# TOP_CTRL_TOP_CTRL_50D80000h register map
Vendor: Texas Instruments
Peripheral module from a debugger description file (folder AM263P).
Registers are 32-bit, read-write, reset 0x0 unless marked. A register's access mark holds for its fields unless they carry their own. Offsets are as the file gives them; lines under a group give offsets from that group; [hi:lo] are bit positions; {n}, {i} and the like mark numbered series; 'fields as' and 'values as' point back to an identical list; <NAME> marks a mode.

## TOP_CTRL
{0x10+4i} TOP_CTRL_EFUSE_DIEID{i} ro (i=0..3) — EFUSE_DIEID{i}.
  [31:0] EFUSE_DIEID{i}_VAL — EFUSE DieID[{32i+31}:{32i}]
{0x20+4i} TOP_CTRL_EFUSE_UID{i} ro (i=0..2) — EFUSE_UID{i}.
  [31:0] EFUSE_UID{i}_VAL — EFUSE UID[{32i+31}:{32i}]- Unique ID
0x2C TOP_CTRL_EFUSE_UID3 ro — EFUSE_UID3.
  [23:0] EFUSE_UID3_VAL — EFUSE UID[120:96]- Unique ID
0x30 TOP_CTRL_EFUSE_DEVICE_TYPE ro — EFUSE_DEVICE_TYPE.
  [15:0] EFUSE_DEVICE_TYPE_VAL — EFUSE Device Type : 0x5 - Test Device 0x3 - General Purpose Device 0x9 - EMU Device 0xA - High Secure
0x34 TOP_CTRL_EFUSE_FROM0_CHECKSUM ro — EFUSE_FROM0_CHECKSUM.
  [31:0] EFUSE_FROM0_CHECKSUM_VAL — 32 bit FROM0 Checksum
0x38 TOP_CTRL_EFUSE_JTAG_USERCODE_ID ro — EFUSE_JTAG_USERCODE_ID.
  [31:0] EFUSE_JTAG_USERCODE_ID_VAL — EFUSE JTAG_USER_CODE_ID[31:0]. Denotes part variant
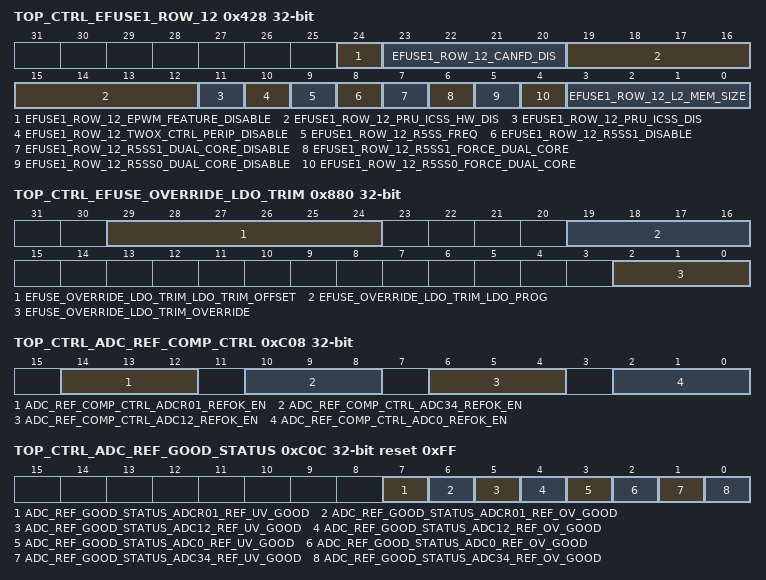
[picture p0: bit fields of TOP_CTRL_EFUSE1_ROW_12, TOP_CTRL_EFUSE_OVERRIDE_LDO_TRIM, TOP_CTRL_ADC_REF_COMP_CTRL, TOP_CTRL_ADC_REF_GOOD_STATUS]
0x428 TOP_CTRL_EFUSE1_ROW_12 ro — EFUSE Row.
  [24] EFUSE1_ROW_12_EPWM_FEATURE_DISABLE — Customer protected features inside PWM IP 1'b0 - All features enabled1'b1 - Customer defined features are protected
  [23:20] EFUSE1_ROW_12_CANFD_DIS — CANFD disables. Bit positions correspond to CAN instance. 1'b0 - CAN is enabled1'b1 - CAN is disabled
  [19:12] EFUSE1_ROW_12_PRU_ICSS_HW_DIS — ICSSM IP feature configuration0x00:EtherCAT is available0x03:EtherCAT is disabled
  [11] EFUSE1_ROW_12_PRU_ICSS_DIS — ICSSM IP disable1'b0 - ICSSM enabled1'b1 - ICSSM disabled
  [10] EFUSE1_ROW_12_TWOX_CTRL_PERIP_DISABLE — 2x control IPs enabled1'b0 - 1x control IPs available (Standard Analog Configuration)1'b1 - (i.e.all) 2x control IPs available (Enhanced Analog Configuration) Refer to device datasheet for more details on the control IP Counts
  [9] EFUSE1_ROW_12_R5SS_FREQ — R5SS Freq1'b0 - 400 MHz1'b1 - 200 MHz
  [8] EFUSE1_ROW_12_R5SS1_DISABLE — R5SS1 Disabled
  [7] EFUSE1_ROW_12_R5SS1_DUAL_CORE_DISABLE — Force Lock step
  [6] EFUSE1_ROW_12_R5SS1_FORCE_DUAL_CORE — Force Dual core
  [5] EFUSE1_ROW_12_R5SS0_DUAL_CORE_DISABLE — Force Lock step
  [4] EFUSE1_ROW_12_R5SS0_FORCE_DUAL_CORE — Force Dual core
  [3:0] EFUSE1_ROW_12_L2_MEM_SIZE — Decides memory size0000L2-3.0 MB0001L2-2.5 MB0010L2-2.0 MB0011L2-1.5 MB0100L2-1.0 MB0101L2-0.5 MBOthers-Reserved
0x500 TOP_CTRL_MAC_ID0 ro — Ethernet MAC address lower 32-bits.
  [31:0] MAC_ID0_MACID_LO — 48-bit Ethernet MAC_ID field [can be used by SW through MMR read] - MAC ID low [32bits]
0x504 TOP_CTRL_MAC_ID1 ro — Ethernet MAC address upper 16-bits.
  [15:0] MAC_ID1_MACID_HI — 48-bit Ethernet MAC_ID field [can be used by SW through MMR read] - MAC ID high [16bits]
0x880 TOP_CTRL_EFUSE_OVERRIDE_LDO_TRIM
  [29:24] EFUSE_OVERRIDE_LDO_TRIM_LDO_TRIM_OFFSET — LDO Fine trim around program point
  [19:16] EFUSE_OVERRIDE_LDO_TRIM_LDO_PROG — LDO programming controls. Adjusts nominal LDO output voltage
  [2:0] EFUSE_OVERRIDE_LDO_TRIM_OVERRIDE — Override EFUSE Value with SW ValueWrite 3'b000 : EFUSE ValueWrite 3'b111 : MMR Value
0xC00 TOP_CTRL_ADC_REFBUF0_CTRL — This register is used to enable or disable ADC Reference buffer 0
  [2:0] ADC_REFBUF0_CTRL_ENABLE — Enables adc reference 0, mask hhv before enable000:Disable111 : Enable
0xC04 TOP_CTRL_ADC_REFBUF1_CTRL — This register is used to enable or disable ADC Reference buffer 1
  [2:0] ADC_REFBUF1_CTRL_ENABLE — Enables adc reference 0, mask hhv before enable000:Disable111 : Enable
0xC08 TOP_CTRL_ADC_REF_COMP_CTRL — This register is used to enable or disable the voltage monitors which measure if the ADC reference voltage is good or not.
  [14:12] ADC_REF_COMP_CTRL_ADCR01_REFOK_EN — Enables reference comparators [ROK2]. This monitors adc5 & adc6 refernce
  [10:8] ADC_REF_COMP_CTRL_ADC34_REFOK_EN — Enables reference comparators [ROK1]. This monitors adc3 & adc4 refernc
  [6:4] ADC_REF_COMP_CTRL_ADC12_REFOK_EN — Enables reference comparators [ROK0B]. This monitors adc1 & adc2 refernce
  [2:0] ADC_REF_COMP_CTRL_ADC0_REFOK_EN — Enables reference comparators [ROK0]. This monitors adc0 refernce
0xC0C TOP_CTRL_ADC_REF_GOOD_STATUS ro reset 0xFF — This register shows the status of ADC reference voltages as measured by the ADC Reference OK voltage monitors.
  [7] ADC_REF_GOOD_STATUS_ADCR01_REF_UV_GOOD — Under Voltage check OK1'b1 - Comparator output is ok for under voltage condition.1'b0 - Comparator output is 1'b0 as threshold condition is not meeting for under voltage condition
  [6] ADC_REF_GOOD_STATUS_ADCR01_REF_OV_GOOD — Over voltage check OK1'b1 - Comparator output is ok for over voltage condition.1'b0 - Comparator output is 1'b0 as threshold condition is not meeting for over voltage condition
  [5] ADC_REF_GOOD_STATUS_ADC12_REF_UV_GOOD — Under Voltage check OK1'b1 - Comparator output is ok for under voltage condition.1'b0 - Comparator output is 1'b0 as threshold condition is not meeting for under voltage condition
  [4] ADC_REF_GOOD_STATUS_ADC12_REF_OV_GOOD — Over voltage check OK1'b1 - Comparator output is ok for over voltage condition.1'b0 - Comparator output is 1'b0 as threshold condition is not meeting for over voltage condition
  [3] ADC_REF_GOOD_STATUS_ADC0_REF_UV_GOOD — Under Voltage check OK1'b1 - Comparator output is ok for under voltage condition.1'b0 - Comparator output is 1'b0 as threshold condition is not meeting for under voltage condition
  [2] ADC_REF_GOOD_STATUS_ADC0_REF_OV_GOOD — Over voltage check OK1'b1 - Comparator output is ok for over voltage condition.1'b0 - Comparator output is 1'b0 as threshold condition is not meeting for over voltage condition
  [1] ADC_REF_GOOD_STATUS_ADC34_REF_UV_GOOD — Under Voltage check OK1'b1 - Comparator output is ok for under voltage condition.1'b0 - Comparator output is 1'b0 as threshold condition is not meeting for under voltage condition
  [0] ADC_REF_GOOD_STATUS_ADC34_REF_OV_GOOD — Over voltage check OK1'b1 - Comparator output is ok for over voltage condition.1'b0 - Comparator output is 1'b0 as threshold condition is not meeting for over voltage condition
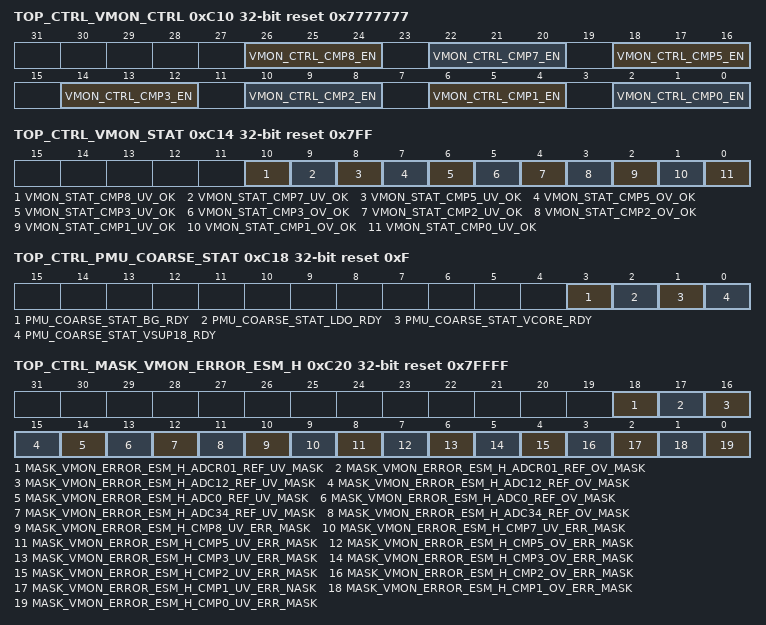
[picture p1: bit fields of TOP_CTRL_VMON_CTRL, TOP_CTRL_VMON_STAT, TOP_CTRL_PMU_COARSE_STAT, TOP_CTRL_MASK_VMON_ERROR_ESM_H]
0xC10 TOP_CTRL_VMON_CTRL reset 0x7777777 — This register is used to enable or disable the power supply voltage monitors present on the device.
  [26:24] VMON_CTRL_CMP8_EN — Enable for VMON comparator 8 Configure it to 3'000 to disable it.
  [22:20] VMON_CTRL_CMP7_EN — Enable for VMON comparator 7 Configure it to 3'000 to disable it.
  [18:16] VMON_CTRL_CMP5_EN — Enable for VMON comparator 5 Configure it to 3'000 to disable it.
  [4n+2:4n] VMON_CTRL_CMP{n}_EN (n=0..3) — Enable for VMON comparator {n} Configure it to 3'000 to disable it.
0xC14 TOP_CTRL_VMON_STAT ro reset 0x7FF — This register shows the status output from the voltage monitors present on the device.
  [10] VMON_STAT_CMP8_UV_OK — VMON status register for comparator 8. 1'b1 - Comparator output is ok for under voltage condition.1'b0 - Comparator output is 1'b0 as threshold condition is not meeting for under voltage condition
  [9] VMON_STAT_CMP7_UV_OK — VMON status register for comparator 7.1'b1 - Comparator output is ok for under voltage condition.1'b0 - Comparator output is 1'b0 as threshold condition is not meeting for under voltage condition
  [8] VMON_STAT_CMP5_UV_OK — VMON status register for comparator 5. 1'b1 - Comparator output is ok for under voltage condition.1'b0 - Comparator output is 1'b0 as threshold condition is not meeting for under voltage condition
  [7] VMON_STAT_CMP5_OV_OK — VMON status register for comparator 5.
  [6] VMON_STAT_CMP3_UV_OK — VMON status register for comparator 3.1'b1 - Comparator output is ok for under voltage condition.1'b0 - Comparator output is 1'b0 as threshold condition is not meeting for under voltage condition
  [5] VMON_STAT_CMP3_OV_OK — VMON status register for comparator 3.1'b1 - Comparator output is ok for over voltage condition.1'b0 - Comparator output is 1'b0 as threshold condition is not meeting for over voltage condition
  [4] VMON_STAT_CMP2_UV_OK — VMON status register for comparator 2. 1'b1 - Comparator output is ok for under voltage condition.1'b0 - Comparator output is 1'b0 as threshold condition is not meeting for under voltage condition
  [3] VMON_STAT_CMP2_OV_OK — VMON status register for comparator 2. 1'b1 - Comparator output is ok for over voltage condition.1'b0 - Comparator output is 1'b0 as threshold condition is not meeting for over voltage condition
  [2] VMON_STAT_CMP1_UV_OK — VMON status register for comparator 1. 1'b1 - Comparator output is ok for under voltage condition.1'b0 - Comparator output is 1'b0 as threshold condition is not meeting for under voltage condition
  [1] VMON_STAT_CMP1_OV_OK — VMON status register for comparator 1. 1'b1 - Comparator output is ok for over voltage condition.1'b0 - Comparator output is 1'b0 as threshold condition is not meeting for over voltage condition
  [0] VMON_STAT_CMP0_UV_OK — VMON status register for comparator 0. 1'b1 - Comparator output is ok for under voltage condition.1'b0 - Comparator output is 1'b0 as threshold condition is not meeting for under voltage condition
0xC18 TOP_CTRL_PMU_COARSE_STAT ro reset 0xF — This register shows the status of coarse voltage monitors present in the device.
  [3] PMU_COARSE_STAT_BG_RDY — Bandgap coarse detection status signals.
  [2] PMU_COARSE_STAT_LDO_RDY — LDO coarse detection status signals.
  [1] PMU_COARSE_STAT_VCORE_RDY — vcore coarse detection status signals.
  [0] PMU_COARSE_STAT_VSUP18_RDY — vdda18 coarse detection status signals.
0xC20 TOP_CTRL_MASK_VMON_ERROR_ESM_H reset 0x7FFFF — This register is used to select the voltage monitors whose Error staus should triggering the ESM High Interrupt.
  [18] MASK_VMON_ERROR_ESM_H_ADCR01_REF_UV_MASK — ADCR01 REF UV VMON Error Mask to ESM Interrupt
  [17] MASK_VMON_ERROR_ESM_H_ADCR01_REF_OV_MASK — ADCR01 REF OV VMON Error Mask to ESM Interrupt
  [16] MASK_VMON_ERROR_ESM_H_ADC12_REF_UV_MASK — ADC34 REF UV VMON Error Mask to ESM Interrupt
  [15] MASK_VMON_ERROR_ESM_H_ADC12_REF_OV_MASK — ADC34 REF OV VMON Error Mask to ESM Interrupt
  [14] MASK_VMON_ERROR_ESM_H_ADC0_REF_UV_MASK — ADC12 REF UV VMON Error Mask to ESM Interrupt
  [13] MASK_VMON_ERROR_ESM_H_ADC0_REF_OV_MASK — ADC12 REF OV VMON Error Mask to ESM Interrupt
  [12] MASK_VMON_ERROR_ESM_H_ADC34_REF_UV_MASK — ADC0 REF UV VMON Error Mask to ESM Interrupt
  [11] MASK_VMON_ERROR_ESM_H_ADC34_REF_OV_MASK — ADC0 REF OV VMON Error Mask to ESM Interrupt
  [10] MASK_VMON_ERROR_ESM_H_CMP8_UV_ERR_MASK — CMP8 UV VMON Error Mask to ESM Interrupt
  [9] MASK_VMON_ERROR_ESM_H_CMP7_UV_ERR_MASK — CMP7 UV VMON Error Mask to ESM Interrupt
  [8] MASK_VMON_ERROR_ESM_H_CMP5_UV_ERR_MASK — CMP5 UV VMON Error Mask to ESM Interrupt
  [7] MASK_VMON_ERROR_ESM_H_CMP5_OV_ERR_MASK — CMP5 OV VMON Error Mask to ESM Interrupt
  [6] MASK_VMON_ERROR_ESM_H_CMP3_UV_ERR_MASK — CMP3 UV VMON Error Mask to ESM Interrupt
  [5] MASK_VMON_ERROR_ESM_H_CMP3_OV_ERR_MASK — CMP3 OV VMON Error Mask to ESM Interrupt
  [4] MASK_VMON_ERROR_ESM_H_CMP2_UV_ERR_MASK — CMP2 UV VMON Error Mask to ESM Interrupt
  [3] MASK_VMON_ERROR_ESM_H_CMP2_OV_ERR_MASK — CMP2 OV VMON Error Mask to ESM Interrupt
  [2] MASK_VMON_ERROR_ESM_H_CMP1_UV_ERR_NASK — CMP1 UV VMON Error Mask to ESM Interrupt
  [1] MASK_VMON_ERROR_ESM_H_CMP1_OV_ERR_MASK — CMP1 OV VMON Error Mask to ESM Interrupt
  [0] MASK_VMON_ERROR_ESM_H_CMP0_UV_ERR_MASK — CMP0 UV VMON Error Mask to ESM Interrupt
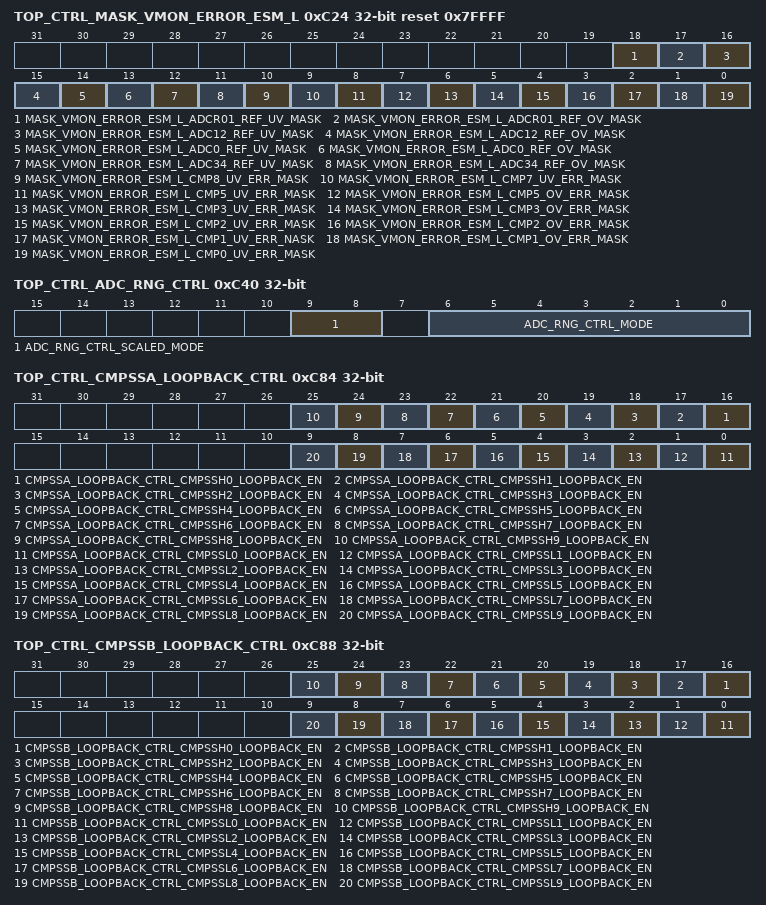
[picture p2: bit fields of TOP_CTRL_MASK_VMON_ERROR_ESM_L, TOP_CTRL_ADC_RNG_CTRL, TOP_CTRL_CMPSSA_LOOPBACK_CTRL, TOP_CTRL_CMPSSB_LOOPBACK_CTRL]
0xC24 TOP_CTRL_MASK_VMON_ERROR_ESM_L reset 0x7FFFF — This register is used to select the voltage monitors whose Error staus should triggering the ESM Low Interrupt.
  [18] MASK_VMON_ERROR_ESM_L_ADCR01_REF_UV_MASK — ADCR01 REF UV VMON Error Mask to ESM Interrupt
  [17] MASK_VMON_ERROR_ESM_L_ADCR01_REF_OV_MASK — ADCR01 REF OV VMON Error Mask to ESM Interrupt
  [16] MASK_VMON_ERROR_ESM_L_ADC12_REF_UV_MASK — ADC34 REF UV VMON Error Mask to ESM Interrupt
  [15] MASK_VMON_ERROR_ESM_L_ADC12_REF_OV_MASK — ADC34 REF OV VMON Error Mask to ESM Interrupt
  [14] MASK_VMON_ERROR_ESM_L_ADC0_REF_UV_MASK — ADC12 REF UV VMON Error Mask to ESM Interrupt
  [13] MASK_VMON_ERROR_ESM_L_ADC0_REF_OV_MASK — ADC12 REF OV VMON Error Mask to ESM Interrupt
  [12] MASK_VMON_ERROR_ESM_L_ADC34_REF_UV_MASK — ADC0 REF UV VMON Error Mask to ESM Interrupt
  [11] MASK_VMON_ERROR_ESM_L_ADC34_REF_OV_MASK — ADC0 REF OV VMON Error Mask to ESM Interrupt
  [10] MASK_VMON_ERROR_ESM_L_CMP8_UV_ERR_MASK — CMP8 UV VMON Error Mask to ESM Interrupt
  [9] MASK_VMON_ERROR_ESM_L_CMP7_UV_ERR_MASK — CMP7 UV VMON Error Mask to ESM Interrupt
  [8] MASK_VMON_ERROR_ESM_L_CMP5_UV_ERR_MASK — CMP5 UV VMON Error Mask to ESM Interrupt
  [7] MASK_VMON_ERROR_ESM_L_CMP5_OV_ERR_MASK — CMP5 OV VMON Error Mask to ESM Interrupt
  [6] MASK_VMON_ERROR_ESM_L_CMP3_UV_ERR_MASK — CMP3 UV VMON Error Mask to ESM Interrupt
  [5] MASK_VMON_ERROR_ESM_L_CMP3_OV_ERR_MASK — CMP3 OV VMON Error Mask to ESM Interrupt
  [4] MASK_VMON_ERROR_ESM_L_CMP2_UV_ERR_MASK — CMP2 UV VMON Error Mask to ESM Interrupt
  [3] MASK_VMON_ERROR_ESM_L_CMP2_OV_ERR_MASK — CMP2 OV VMON Error Mask to ESM Interrupt
  [2] MASK_VMON_ERROR_ESM_L_CMP1_UV_ERR_NASK — CMP1 UV VMON Error Mask to ESM Interrupt
  [1] MASK_VMON_ERROR_ESM_L_CMP1_OV_ERR_MASK — CMP1 OV VMON Error Mask to ESM Interrupt
  [0] MASK_VMON_ERROR_ESM_L_CMP0_UV_ERR_MASK — CMP0 UV VMON Error Mask to ESM Interrupt
0xC30 TOP_CTRL_MASK_ANA_ISO — This register is used to prevent the Coarse voltage monitor from triggering a faulty SOC reset due to a momentary supply glitch caused when enabling ADC reference buffers.
  [2:0] MASK_ANA_ISO_MASK — Mask the Ana ISO generating SOC reset due to a glitch on VDD OK.Used during Trim updates to the analog or during ADC Refbuf enable
0xC34 TOP_CTRL_VMON_FILTER_CTRL — This register is used to configure the filter present on the Voltage monitor outputs.
  [1:0] VMON_FILTER_CTRL_SELECT_VALUE — VMON FILTER control select2'b00 : no filtering [default]2'b01 : filtering for 4.8us2'b10 : filtering for 9.6us2'b11 : filtering for 14.4us**Note: This bit will only be reset by PORz.
0xC40 TOP_CTRL_ADC_RNG_CTRL — ADC range control in single ended mode.
  [9:8] ADC_RNG_CTRL_SCALED_MODE — This bit controls scaled mode for resolver adc's2'b0 --> Normal output2'b1 --> scale 04223in 04095[efectively supporting 0-3.3V in 12 bit space] [in 12bit mode only]bit8 corresponds to adc_r0bit9 corresponds to adc_r1
  [6:0] ADC_RNG_CTRL_MODE — Single-Ended Mode, 0 ADC Input supports 0 to Vref*32/1. 0V corresponds to all zero code and 3.2V corresponds to all 1 or code40951 ADC Input supports Vref*1/18 to Vref*33/18. Vref*1/18 corresponds to all zero code and Vref*32/18 corresponds to all 1 or code4095 Differential Mode Don't take any effect on the system Default is 0Vcm=Vref*33/18/2 Vref = ADC reference voltage, typically 1.8V
{0xC44+4i} TOP_CTRL_ADC{i}_OSD_CHEN (i=0..4) — ADC Channel enable for Open Short detection.
  [5:0] ADC{i}_OSD_CHEN_CH_OSD_EN — Controls enabling the channel for ADC when set to 1'b1. Each bit corresponds to the respective ADC channel -Bit 0 - ch0_osd_enBit 1 - ch1_osd_enBit 2 - ch2_osd_enBit 3 - ch3_osd_enBit 4 - ch4_osd_enBit 5 - ch5_osd_en
{0xC58+4i} TOP_CTRL_ADC{i}_OSD_CTRL (i=0..4) — ADC open short function controls.
  [2:0] ADC{i}_OSD_CTRL_FUNCTION — Controls the shorting of internal 5K, 11K resistor to the ADC channel for open short detection [Default 0] value function Impedance 5K voltage 7K voltage3'b000 Zero Scale 5K || 7K vssa vssa3'b001 Zero Scale 5K vssa open3'b010 Zero Scale 7K open vssa3'b011 Full Scale 5K || 7K vdd_3p3v vdd_3p3v3'b100 Full Scale 5K vdd_3p3v open3'b101 Full Scale 7K open vdd_3p3v3'b110 5/12 Scale 5K || 7K vssa vdd_3p3v3'b111 7/12 Scale K || 7K vdd_3p3v vssa*all resistor values can vary by + 30%**Function is only correct if the external circuits driving the analog port are high impedance. If the port is connected to external circuits the customer will have to calculate the expected output.
0xC80 TOP_CTRL_ADC_LOOPBACK_CTRL — Controls loopback safety functionality from DAC output to ADC inputs.
  [0] ADC_LOOPBACK_CTRL_ADC_LOOPBACK_EN — Controls ADC loopback 1'b1: loopback enabled,1'b0: loopback disabled[default]
0xC84 TOP_CTRL_CMPSSA_LOOPBACK_CTRL — Controls loopback safety functionality from DAC output to ADC inputs.
  [n+16] CMPSSA_LOOPBACK_CTRL_CMPSSH{n}_LOOPBACK_EN (n=0..9) — Controls CMPSS loopback enable1'b1 : loopback enabled, 1'b0 : loopback disabled[default]
  [n] CMPSSA_LOOPBACK_CTRL_CMPSSL{n}_LOOPBACK_EN (n=0..9) — Controls CMPSS loopback enable1'b1 : loopback enabled, 1'b0 : loopback disabled[default]
0xC88 TOP_CTRL_CMPSSB_LOOPBACK_CTRL — Controls loopback safety functionality from DAC output to ADC inputs.
  [n+16] CMPSSB_LOOPBACK_CTRL_CMPSSH{n}_LOOPBACK_EN (n=0..9) — Controls CMPSS loopback enable1'b1 : loopback enabled, 1'b0 : loopback disabled[default]
  [n] CMPSSB_LOOPBACK_CTRL_CMPSSL{n}_LOOPBACK_EN (n=0..9) — Controls CMPSS loopback enable1'b1 : loopback enabled, 1'b0 : loopback disabled[default]
0xC8C TOP_CTRL_ADCR01_OSD_CHEN — ADCR Channel enable for Open Short detection.
  [7:0] ADCR01_OSD_CHEN_CH_OSD_EN — Controls enabling the channel for ADC when set to 1'b1. Each bit corresponds to the respective ADC channel -Bit 0 - ch0_osd_enBit 1 - ch1_osd_enBit 2 - ch2_osd_enBit 3 - ch3_osd_enBit 4 - ch4_osd_enBit 5 - ch5_osd_en
0xC90 TOP_CTRL_ADCR01_OSD_CTRL — ADCR open short function controls.
  [2:0] ADCR01_OSD_CTRL_FUNCTION — Controls the shorting of internal 5K, 11K resistor to the ADC channel for open short detection [Default 0] value function Impedance 5K voltage 7K voltage3'b000 Zero Scale 5K || 7K vssa vssa3'b001 Zero Scale 5K vssa open3'b010 Zero Scale 7K open vssa3'b011 Full Scale 5K || 7K vdd_3p3v vdd_3p3v3'b100 Full Scale 5K vdd_3p3v open3'b101 Full Scale 7K open vdd_3p3v3'b110 5/12 Scale 5K || 7K vssa vdd_3p3v3'b111 7/12 Scale K || 7K vdd_3p3v vssa*all resistor values can vary by + 30%**Function is only correct if the external circuits driving the analog port are high impedance. If the port is connected to external circuits the customer will have to calculate the expected output.
0xC94 TOP_CTRL_ADC_REFBUF2_CTRL — This register is used to enable or disable ADC Reference buffer 2
  [2:0] ADC_REFBUF2_CTRL_ENABLE — Enables adc reference 0, mask hhv before enable000:Disable111 : Enable
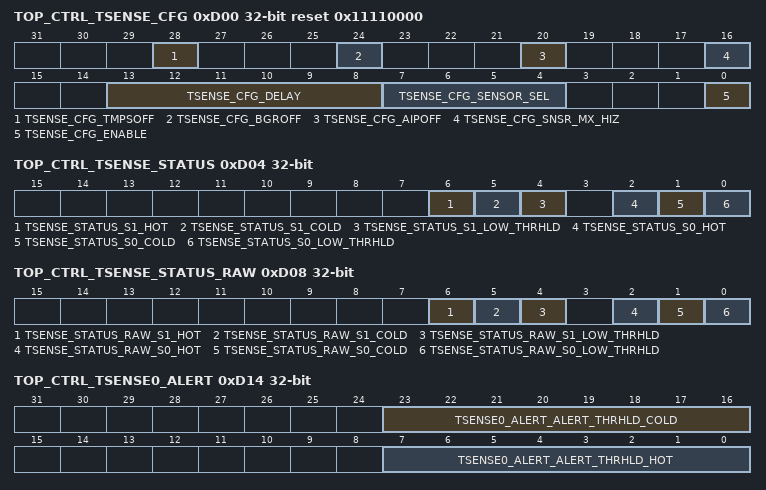
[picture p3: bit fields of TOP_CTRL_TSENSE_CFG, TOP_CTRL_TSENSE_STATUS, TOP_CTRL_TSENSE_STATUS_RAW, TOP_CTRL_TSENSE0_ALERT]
0xD00 TOP_CTRL_TSENSE_CFG reset 0x11110000 — This register is used to enableand configure the Teperature sensors present in the device .
  [28] TSENSE_CFG_TMPSOFF — BandGap on/off control 1'b1 : off 1'b0 : on**Note: This bit will only be reset by PORz.
  [24] TSENSE_CFG_BGROFF — BandGap on/off control 1'b1 : off 1'b0 : on**Note: This bit will only be reset by PORz.
  [20] TSENSE_CFG_AIPOFF — 1'b1 : iddq mode select 1'b0 : normal mode**Note: This bit will only be reset by PORz.
  [16] TSENSE_CFG_SNSR_MX_HIZ — Sensor mux hiz control1'b0 : normal operation. Mux will select either one of the anlaog sensor 1'b1 : mux will be high impedence**Note: This bit will only be reset by PORz.
  [13:8] TSENSE_CFG_DELAY — Number of wait clock cycles between each TMPS Readout. Configure a Non zero value as delay value since configuring 0 is not allowed**Note: This bit will only be reset by PORz.
  [7:4] TSENSE_CFG_SENSOR_SEL — Sensor Selection sensor enable bits for each sensor 1'b0 : sensor disable 1'b1 : sensor enablebit3: temp_sensor3bit2: temp_sensor2bit1: temp_sensor1bit0: temp_sensor0**Note: This bit will only be reset by PORz.
  [0] TSENSE_CFG_ENABLE — Temperature controller enable**Note: This bit will only be reset by PORz.
0xD04 TOP_CTRL_TSENSE_STATUS ro — This register shows the status of Temperature comparator events which are unmasked.
  [6] TSENSE_STATUS_S1_HOT — temperature Sensor 1 hot event detect0 : event not occured1 : event occurred**Note: This bit will only be reset by PORz.
  [5] TSENSE_STATUS_S1_COLD — temperature Sensor 1 cold event detect1'b0 : event not occured1'b1 : event occurred**Note: This bit will only be reset by PORz.
  [4] TSENSE_STATUS_S1_LOW_THRHLD — temperature Sensor 1 low threshold event detect1'b0 : event not occured1'b1 : event occurred**Note: This bit will only be reset by PORz.
  [2] TSENSE_STATUS_S0_HOT — temperature Sensor 0 hot event detect1'b0 : event not occured1'b1 : event occurred**Note: This bit will only be reset by PORz.
  [1] TSENSE_STATUS_S0_COLD — temperature Sensor 0 cold event detect0 : event not occured1 : event occurred**Note: This bit will only be reset by PORz.
  [0] TSENSE_STATUS_S0_LOW_THRHLD — temperature Sensor 0 low threshold event detect0 : event not occured1 : event occurred**Note: This bit will only be reset by PORz.
0xD08 TOP_CTRL_TSENSE_STATUS_RAW ro — This register shows the status of all Temperature comparators events including masked events.
  [6] TSENSE_STATUS_RAW_S1_HOT — temperature Sensor 1 hot event detect0 : event not occured1 : event occurred**Note: This bit will only be reset by PORz.
  [5] TSENSE_STATUS_RAW_S1_COLD — temperature Sensor 1 cold event detect0 : event not occured1 : event occurred**Note: This bit will only be reset by PORz.
  [4] TSENSE_STATUS_RAW_S1_LOW_THRHLD — temperature Sensor 1 low threshold event detect0 : event not occured1 : event occurred**Note: This bit will only be reset by PORz.
  [2] TSENSE_STATUS_RAW_S0_HOT — temperature Sensor 0 hot event detect0 : event not occured1 : event occurred**Note: This bit will only be reset by PORz.
  [1] TSENSE_STATUS_RAW_S0_COLD — temperature Sensor 0 cold event detect0 : event not occured1 : event occurred**Note: This bit will only be reset by PORz.
  [0] TSENSE_STATUS_RAW_S0_LOW_THRHLD — temperature Sensor 0 low threshold event detect0 : event not occured1 : event occurred**Note: This bit will only be reset by PORz.
0xD14 TOP_CTRL_TSENSE0_ALERT — This register is used to configure the temperature thresholds for Temp Sensor 0 for generating Alert Interrupts.
  [23:16] TSENSE0_ALERT_ALERT_THRHLD_COLD — cold threshold/low temp threshold**Note: This bit will only be reset by PORz.
  [7:0] TSENSE0_ALERT_ALERT_THRHLD_HOT — Hot threshold/high temp threshold**Note: This bit will only be reset by PORz.
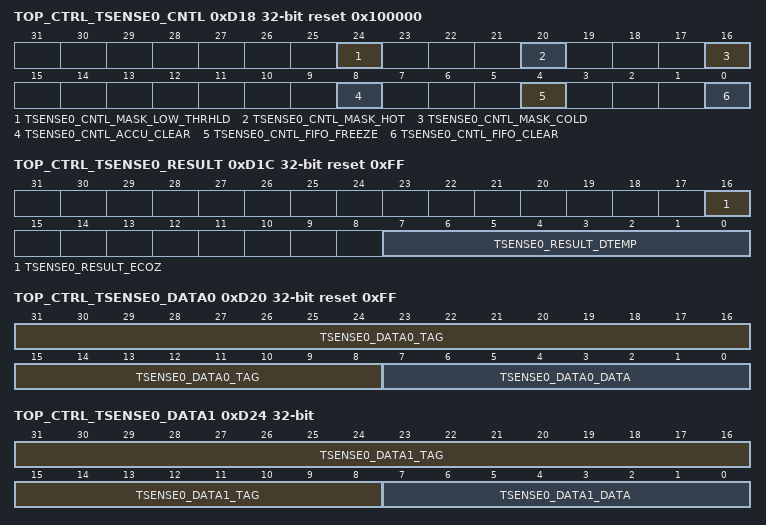
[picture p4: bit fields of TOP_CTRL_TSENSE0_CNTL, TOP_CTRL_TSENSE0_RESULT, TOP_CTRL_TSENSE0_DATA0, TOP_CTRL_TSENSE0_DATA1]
0xD18 TOP_CTRL_TSENSE0_CNTL reset 0x100000 — This register is used to control and configure Temperature sensor 0
  [24] TSENSE0_CNTL_MASK_LOW_THRHLD — mask low threshold comparator output**Note: This bit will only be reset by PORz.
  [20] TSENSE0_CNTL_MASK_HOT — Mask hot comparator output**Note: This bit will only be reset by PORz.
  [16] TSENSE0_CNTL_MASK_COLD — mask cold comparator output**Note: This bit will only be reset by PORz.
  [8] TSENSE0_CNTL_ACCU_CLEAR — Accumulator clear**Note: This bit will only be reset by PORz.
  [4] TSENSE0_CNTL_FIFO_FREEZE — fifo freeze**Note: This bit will only be reset by PORz.
  [0] TSENSE0_CNTL_FIFO_CLEAR — fifo clear**Note: This bit will only be reset by PORz.
0xD1C TOP_CTRL_TSENSE0_RESULT ro reset 0xFF — This register shows the most recent temperature readout and status of any ongoing Temperature measurement from Temperature Sensor 0
  [16] TSENSE0_RESULT_ECOZ — Conversion in Progress.1'b1 : Conversion on going1'b0 : conversion completed**Note: This bit will only be reset by PORz.
  [7:0] TSENSE0_RESULT_DTEMP — Temp Code readout**Note: This bit will only be reset by PORz.
0xD20 TOP_CTRL_TSENSE0_DATA0 ro reset 0xFF — Temp Sensor 0 Result FIFO Register 0
  [31:8] TSENSE0_DATA0_TAG — Tag for temperature sesnor 0 Data 0 measured**Note: This bit will only be reset by PORz.
  [7:0] TSENSE0_DATA0_DATA — Temperature Sensor0 FIFO data 0**Note: This bit will only be reset by PORz.
0xD24 TOP_CTRL_TSENSE0_DATA1 ro — Temp Sensor 0 Result FIFO Register 1
  [31:8] TSENSE0_DATA1_TAG — Tag for temperature sesnor 0 Data 1 measured**Note: This bit will only be reset by PORz.
  [7:0] TSENSE0_DATA1_DATA — Temperature Sensor0 FIFO data 1**Note: This bit will only be reset by PORz.
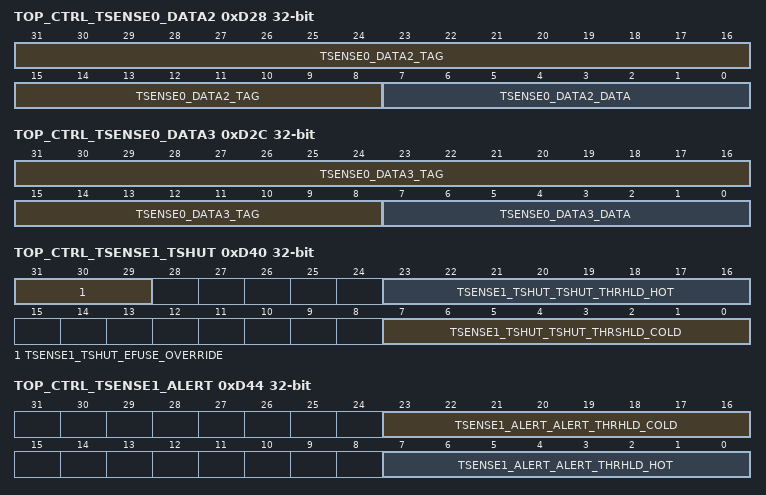
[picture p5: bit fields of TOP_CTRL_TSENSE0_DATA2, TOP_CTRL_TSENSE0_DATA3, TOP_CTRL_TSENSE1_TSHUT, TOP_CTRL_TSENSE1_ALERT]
0xD28 TOP_CTRL_TSENSE0_DATA2 ro — Temp Sensor 0 Result FIFO Register 2
  [31:8] TSENSE0_DATA2_TAG — Tag for temperature sesnor 0 Data 2 measured**Note: This bit will only be reset by PORz.
  [7:0] TSENSE0_DATA2_DATA — Temperature Sensor 0 FIFO data 2**Note: This bit will only be reset by PORz.
0xD2C TOP_CTRL_TSENSE0_DATA3 ro — Temp Sensor 0 Result FIFO Register 3
  [31:8] TSENSE0_DATA3_TAG — Tag for temperature sesnor 0 Data 3 measured**Note: This bit will only be reset by PORz.
  [7:0] TSENSE0_DATA3_DATA — Temperature Sensor 0 FIFO data 3**Note: This bit will only be reset by PORz.
0xD30 TOP_CTRL_TSENSE0_ACCU ro — Temp Sensor 0 Result Accumulator Register.
  [31:0] TSENSE0_ACCU_CUMUL — cumulative sum of past DTEMPs**Note: This bit will only be reset by PORz.
0xD40 TOP_CTRL_TSENSE1_TSHUT — This register is used to override the factory specified Tshut temperature with an application specific Tshut temperature for Temperature sensor 1
  [31:29] TSENSE1_TSHUT_EFUSE_OVERRIDE — Efuse override3'b000 -- Value from EFUSE is used as tshut hot and tshut cold thresholds3'b111 - Overide value takes effect**Note: This bit will only be reset by PORz.
  [23:16] TSENSE1_TSHUT_TSHUT_THRHLD_HOT — tshut hot threshold. Reads efuse value untill overwritten with override = 111**Note: This bit will only be reset by PORz.
  [7:0] TSENSE1_TSHUT_TSHUT_THRSHLD_COLD — tshut cold threshold. Reads efuse value untill overwritten with override = 111**Note: This bit will only be reset by PORz.
0xD44 TOP_CTRL_TSENSE1_ALERT — This register is used to configure the temperature thresholds for Temp Sensor 1 for generating Alert Interrupts.
  [23:16] TSENSE1_ALERT_ALERT_THRHLD_COLD — cold threshold/low temp threshold**Note: This bit will only be reset by PORz.
  [7:0] TSENSE1_ALERT_ALERT_THRHLD_HOT — Hot threshold/high temp threshold**Note: This bit will only be reset by PORz.
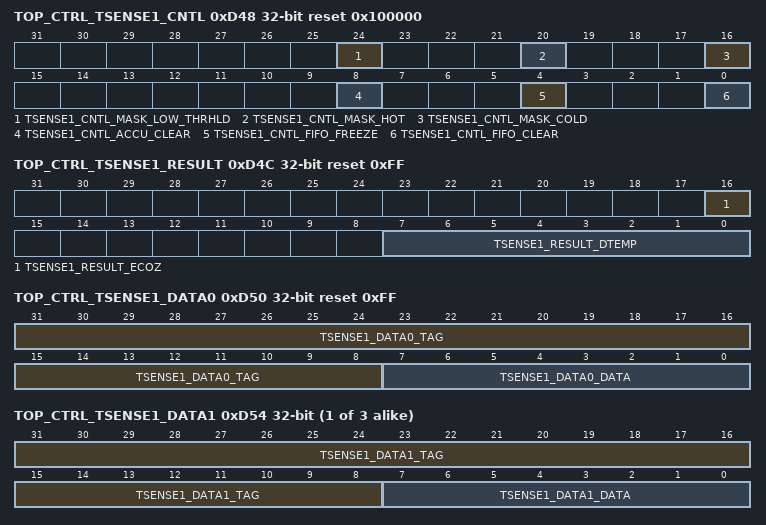
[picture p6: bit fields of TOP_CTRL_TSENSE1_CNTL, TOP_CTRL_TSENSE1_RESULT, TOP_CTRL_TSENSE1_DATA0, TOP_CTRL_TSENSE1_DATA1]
0xD48 TOP_CTRL_TSENSE1_CNTL reset 0x100000 — This register is used to control and configure Temperature sensor 1
  [24] TSENSE1_CNTL_MASK_LOW_THRHLD — mask low threshold comparator output**Note: This bit will only be reset by PORz.
  [20] TSENSE1_CNTL_MASK_HOT — Mask hot comparator output**Note: This bit will only be reset by PORz.
  [16] TSENSE1_CNTL_MASK_COLD — mask cold comparator output**Note: This bit will only be reset by PORz.
  [8] TSENSE1_CNTL_ACCU_CLEAR — Accumulator clear**Note: This bit will only be reset by PORz.
  [4] TSENSE1_CNTL_FIFO_FREEZE — fifo freeze**Note: This bit will only be reset by PORz.
  [0] TSENSE1_CNTL_FIFO_CLEAR — fifo clear**Note: This bit will only be reset by PORz.
0xD4C TOP_CTRL_TSENSE1_RESULT ro reset 0xFF — This register shows the most recent temperature readout and status of any ongoing Temperature measurement from Temperature Sensor 1
  [16] TSENSE1_RESULT_ECOZ — Conversion in Progress.1'b1 : Conversion on going1'b0 : conversion completed**Note: This bit will only be reset by PORz.
  [7:0] TSENSE1_RESULT_DTEMP — Temp Code readout**Note: This bit will only be reset by PORz.
0xD50 TOP_CTRL_TSENSE1_DATA0 ro reset 0xFF — Temp Sensor 1 Result FIFO Register 0
  [31:8] TSENSE1_DATA0_TAG — Tag for temperature sesnor 1 Data 0 measured**Note: This bit will only be reset by PORz.
  [7:0] TSENSE1_DATA0_DATA — Temperature sensor 1 FIFO Data 0**Note: This bit will only be reset by PORz.
{0xD50+4i} TOP_CTRL_TSENSE1_DATA{i} ro (i=1..3) — Temp Sensor 1 Result FIFO Register {i}
  [31:8] TSENSE1_DATA{i}_TAG — Temperature sensor 1 FIFO Data {i}**Note: This bit will only be reset by PORz.
  [7:0] TSENSE1_DATA{i}_DATA — Temperature sensor 1 FIFO Data {i}**Note: This bit will only be reset by PORz.
0xD60 TOP_CTRL_TSENSE1_ACCU ro — Temp Sensor 1 Result Accumulator Register.
  [31:0] TSENSE1_ACCU_CUMUL — cumulative sum of past DTEMPs**Note: This bit will only be reset by PORz.
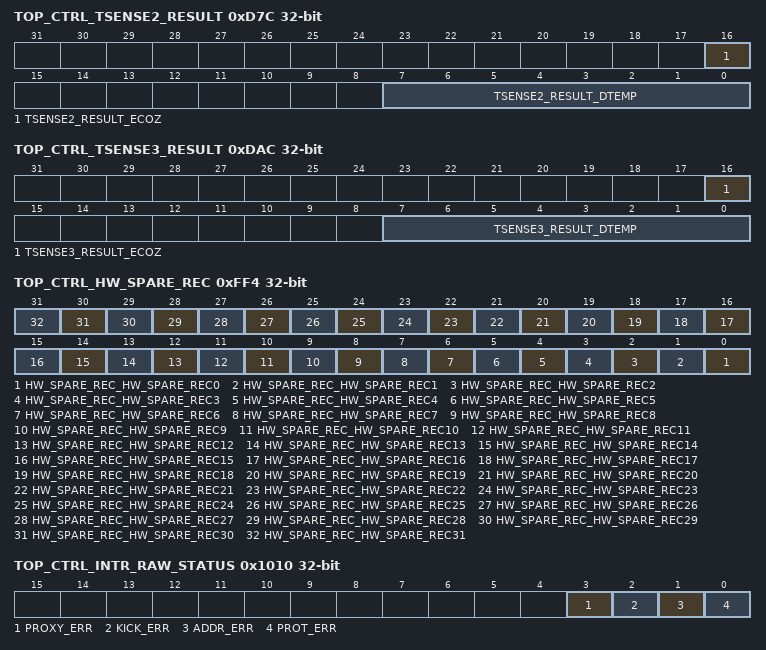
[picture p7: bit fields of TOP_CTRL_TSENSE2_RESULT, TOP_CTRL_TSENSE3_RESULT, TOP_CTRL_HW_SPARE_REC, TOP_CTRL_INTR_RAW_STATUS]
0xD7C TOP_CTRL_TSENSE2_RESULT ro — This register shows the most recent temperature readout and status of any ongoing Temperature measurement from Temperature Sensor 2
  [16] TSENSE2_RESULT_ECOZ — Conversion in Progress.1'b1 : Conversion on going1'b0 : conversion completed**Note: This bit will only be reset by PORz.
  [7:0] TSENSE2_RESULT_DTEMP — Temp Code readout**Note: This bit will only be reset by PORz.
0xDAC TOP_CTRL_TSENSE3_RESULT ro — This register shows the most recent temperature readout and status of any ongoing Temperature measurement from Temperature Sensor 3
  [16] TSENSE3_RESULT_ECOZ — Conversion in Progress.1'b1 : Conversion on going1'b0 : conversion completed**Note: This bit will only be reset by PORz.
  [7:0] TSENSE3_RESULT_DTEMP — Temp Code readout**Note: This bit will only be reset by PORz.
{0xFD0+4i} TOP_CTRL_HW_SPARE_RW{i} (i=0..3) — HW_SPARE_RW{i}.
  [31:0] HW_SPARE_RW{i}_HW_SPARE_RW{i} — Reserved for HW R&D
{0xFE0+4i} TOP_CTRL_HW_SPARE_RO{i} ro (i=0..3) — HW_SPARE_RO{i}.
  [31:0] HW_SPARE_RO{i}_HW_SPARE_RO{i} — Reserved for HW R&D
0xFF0 TOP_CTRL_HW_SPARE_WPH — HW_SPARE_WPH.
  [31:0] HW_SPARE_WPH_HW_SPARE_WPH — Reserved for HW R&D
0xFF4 TOP_CTRL_HW_SPARE_REC — HW_SPARE_REC.
  [n] HW_SPARE_REC_HW_SPARE_REC{n} (n=0..31) — Reserved for HW R&D
0x1008 TOP_CTRL_LOCK0_KICK0 — - KICK0 component.
  [31:0] LOCK0_KICK0 — - KICK0 component
0x100C TOP_CTRL_LOCK0_KICK1 — - KICK1 component.
  [31:0] LOCK0_KICK1 — - KICK1 component
0x1010 TOP_CTRL_INTR_RAW_STATUS access not given — Interrupt Raw Status/Set Register.
  [3] PROXY_ERR — Proxy0 access violation error. Raw status is read. Write a 1 to set the status. Writing a 0 has no effect. (access R/W1TS)
  [2] KICK_ERR — Kick access violation error. Raw status is read. Write a 1 to set the status. Writing a 0 has no effect. (access R/W1TS)
  [1] ADDR_ERR — Addressing violation error. Raw status is read. Write a 1 to set the status. Writing a 0 has no effect. (access R/W1TS)
  [0] PROT_ERR — Protection violation error. Raw status is read. Write a 1 to set the status. Writing a 0 has no effect. (access R/W1TS)
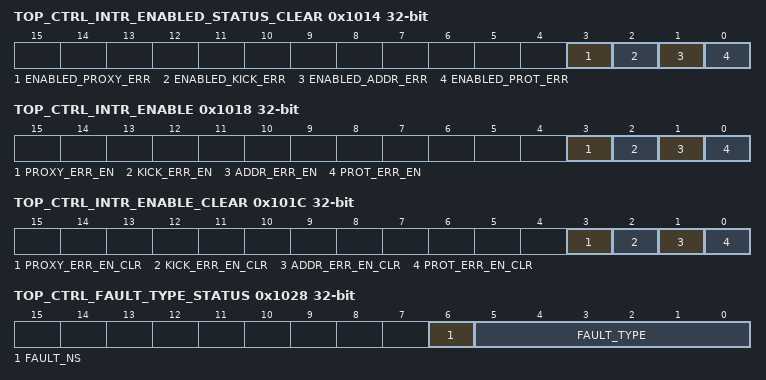
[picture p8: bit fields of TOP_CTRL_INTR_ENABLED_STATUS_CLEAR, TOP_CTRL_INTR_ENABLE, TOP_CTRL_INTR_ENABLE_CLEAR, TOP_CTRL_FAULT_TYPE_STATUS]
0x1014 TOP_CTRL_INTR_ENABLED_STATUS_CLEAR access not given — Interrupt Enabled Status/Clear register.
  [3] ENABLED_PROXY_ERR — Proxy0 access violation error. Enabled status is read. Write a 1 to clear the status. Writing a 0 has no effect. (access R/W1TC)
  [2] ENABLED_KICK_ERR — Kick access violation error. Enabled status is read. Write a 1 to clear the status. Writing a 0 has no effect. (access R/W1TC)
  [1] ENABLED_ADDR_ERR — Addressing violation error. Enabled status is read. Write a 1 to clear the status. Writing a 0 has no effect. (access R/W1TC)
  [0] ENABLED_PROT_ERR — Protection violation error. Enabled status is read. Write a 1 to clear the status. Writing a 0 has no effect. (access R/W1TC)
0x1018 TOP_CTRL_INTR_ENABLE access not given — Interrupt Enable register.
  [3] PROXY_ERR_EN — Proxy0 access violation error enable. Write a 1 to set the enable. Writing a 0 has no effect. (access R/W1TS)
  [2] KICK_ERR_EN — Kick access violation error enable. Write a 1 to set the enable. Writing a 0 has no effect. (access R/W1TS)
  [1] ADDR_ERR_EN — Addressing violation error enable. Write a 1 to set the enable. Writing a 0 has no effect. (access R/W1TS)
  [0] PROT_ERR_EN — Protection violation error enable. Write a 1 to set the enable. Writing a 0 has no effect. (access R/W1TS)
0x101C TOP_CTRL_INTR_ENABLE_CLEAR access not given — Interrupt Enable Clear register.
  [3] PROXY_ERR_EN_CLR — Proxy0 access violation error enable clear. Write a 1 to clear the enable. Writing a 0 has no effect. (access R/W1TC)
  [2] KICK_ERR_EN_CLR — Kick access violation error enable clear. Write a 1 to clear the enable. Writing a 0 has no effect. (access R/W1TC)
  [1] ADDR_ERR_EN_CLR — Addressing violation error enable clear. Write a 1 to clear the enable. Writing a 0 has no effect. (access R/W1TC)
  [0] PROT_ERR_EN_CLR — Protection violation error enable clear. Write a 1 to clear the enable. Writing a 0 has no effect. (access R/W1TC)
0x1020 TOP_CTRL_EOI — EOI register.
  [7:0] EOI_VECTOR — EOI vector value. Write this with interrupt distribution value in the chip.
0x1024 TOP_CTRL_FAULT_ADDRESS ro — Fault Address register.
  [31:0] FAULT_ADDR — Fault Address.
0x1028 TOP_CTRL_FAULT_TYPE_STATUS ro — Fault Type Status register.
  [6] FAULT_NS — Non-secure access.
  [5:0] FAULT_TYPE — Fault Type 10_0000 = Supervisor read fault - priv = 1 dir = 1 dtype != 1 01_0000 = Supervisor write fault - priv = 1 dir = 0 00_1000 = Supervisor execute fault - priv = 1 dir = 1 dtype = 1 00_0100 = User read fault - priv = 0 dir = 1 dtype = 1 00_0010 = User write fault - priv = 0 dir = 0 00_0001 = User execute fault - priv = 0 dir = 1 dtype = 1 00_0000 = No fault
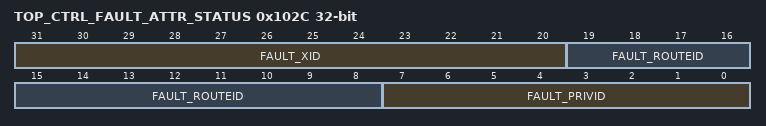
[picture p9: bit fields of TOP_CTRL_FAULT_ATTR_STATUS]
0x102C TOP_CTRL_FAULT_ATTR_STATUS ro — Fault Attribute Status register.
  [31:20] FAULT_XID — XID.
  [19:8] FAULT_ROUTEID — Route ID.
  [7:0] FAULT_PRIVID — Privilege ID.
0x1030 TOP_CTRL_FAULT_CLEAR wo — Fault Clear register.
  [0] FAULT_CLR — Fault clear. Writing a 1 clears the current fault. Writing a 0 has no effect.
